# MCXA156 register map
Vendor: nxp.com; File version: 1.0
CPU: CM33 r2p0, little endian, no MPU, FPU, VTOR, 3 interrupt priority bits
Registers are 32-bit, read-write, reset 0x0 unless marked. A register's access mark holds for its fields unless they carry their own. Offsets are from the block's base; [hi:lo] are bit positions; 'fields as' and 'values as' point back to an identical list.

## SCG0 — SCG
Base 0x4008F000
0x00 VERID ro — Version ID Register
  [31:0] VERSION — SCG Version Number
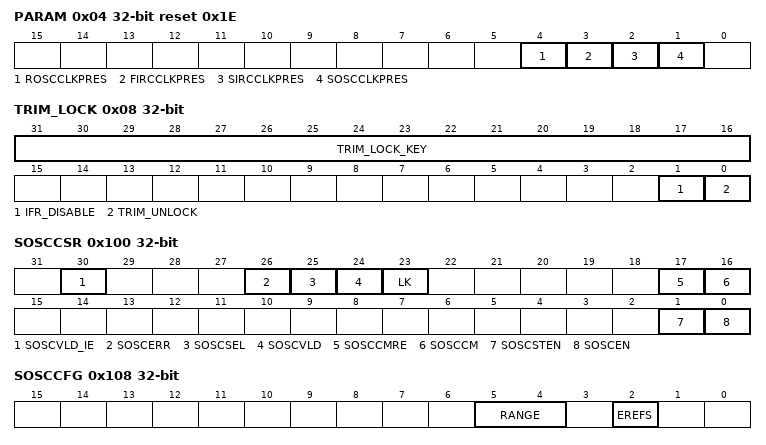
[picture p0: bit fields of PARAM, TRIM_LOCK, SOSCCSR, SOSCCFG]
0x04 PARAM ro reset 0x1E — Parameter Register
  [4] ROSCCLKPRES — ROSC Clock Present
    0=NOPRES (ROSC clock source is not present); 1=PRES (ROSC clock source is present)
  [3] FIRCCLKPRES — FIRC Clock Present
    0=NOPRES (FIRC clock source is not present); 1=PRES (FIRC clock source is present)
  [2] SIRCCLKPRES — SIRC Clock Present
    0=NOPRES (SIRC clock source is not present); 1=PRES (SIRC clock source is present)
  [1] SOSCCLKPRES — SOSC Clock Present
    0=NOPRES (SOSC clock source is not present); 1=PRES (SOSC clock source is present)
0x08 TRIM_LOCK
  [31:16] TRIM_LOCK_KEY
  [1] IFR_DISABLE
    0=ENABLED (IFR write access to SCG trim registers not disabled. The SCG Trim registers are reprogrammed with the IFR values after any system reset.); 1=DISABLED (IFR write access to SCG trim registers during system reset is blocked.)
  [0] TRIM_UNLOCK
    0=LOCKED (SCG Trim Registers locked and not writable.); 1=NOT_LOCKED (SCG Trim registers unlocked and writable.)
0x10 CSR ro reset 0x3000000 — Clock Status Register
  [26:24] SCS — System Clock Source
    1=SOSC; 2=SIRC; 3=FIRC; 4=ROSC
0x14 RCCR reset 0x3000000 — Run Clock Control Register
  [26:24] SCS — System Clock Source
    1=SOSC; 2=SIRC; 3=FIRC; 4=ROSC
0x100 SOSCCSR — SOSC Control Status Register
  [30] SOSCVLD_IE — SOSC Valid Interrupt Enable
    0=NOT_SOSC (SOSCVLD interrupt is not enabled); 1=SOSC (SOSCVLD interrupt is enabled)
  [26] SOSCERR write-1-clears — SOSC Clock Error
    0=DISABLED_OR_NO_ERROR (SOSC Clock Monitor is disabled or has not detected an error); 1=ENABLED_AND_ERROR (SOSC Clock Monitor is enabled and detected an error)
  [25] SOSCSEL ro — SOSC Selected
    0=NOT_SOSC (SOSC is not the system clock source); 1=SOSC (SOSC is the system clock source)
  [24] SOSCVLD ro — SOSC Valid
    0=DISABLED (SOSC is not enabled or clock is not valid); 1=ENABLED (SOSC is enabled and output clock is valid)
  [23] LK — Lock Register
    0=WRITE_ENABLED (This Control Status Register can be written); 1=WRITE_DISABLED (This Control Status Register cannot be written)
  [17] SOSCCMRE — SOSC Clock Monitor Reset Enable
    0=GENERATE_INTERRUPT (Clock monitor generates an interrupt when an error is detected); 1=GENERATE_RESET (Clock monitor generates a reset when an error is detected)
  [16] SOSCCM — SOSC Clock Monitor Enable
    0=DISABLED (SOSC Clock Monitor is disabled); 1=ENABLED (SOSC Clock Monitor is enabled)
  [1] SOSCSTEN — SOSC Stop Enable
    0=DISABLED (SOSC is disabled in Deep Sleep mode); 1=ENABLED (SOSC is enabled in Deep Sleep mode only if SOSCEN is set)
  [0] SOSCEN — SOSC Enable
    0=DISABLED (SOSC is disabled); 1=ENABLED (SOSC is enabled)
0x108 SOSCCFG — SOSC Configuration Register
  [5:4] RANGE — SOSC Range Select
    0=FREQ_16TO20MHz (Frequency range select of 8-16 MHz.); 1=LOW_FREQ (Frequency range select of 16-25 MHz.); 2=MEDIUM_FREQ (Frequency range select of 25-40 MHz.); 3=HIGH_FREQ (Frequency range select of 40-50 MHz.)
  [2] EREFS — External Reference Select
    0=EXTERNAL (External reference clock selected.); 1=INTERNAL (Internal crystal oscillator of OSC selected.)
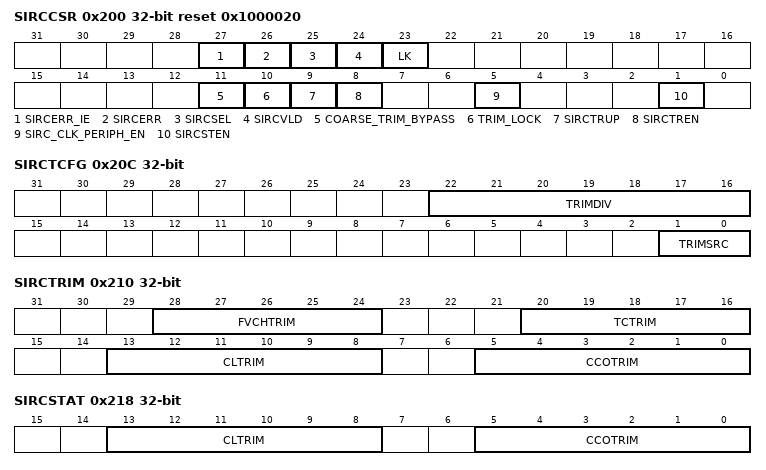
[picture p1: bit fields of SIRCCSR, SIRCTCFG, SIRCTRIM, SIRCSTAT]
0x200 SIRCCSR reset 0x1000020 — SIRC Control Status Register
  [27] SIRCERR_IE — SIRC Clock Error Interrupt Enable
    0=ERROR_NOT_DETECTED (SIRCERR interrupt is not enabled); 1=ERROR_DETECTED (SIRCERR interrupt is enabled)
  [26] SIRCERR write-1-clears — SIRC Clock Error
    0=ERROR_NOT_DETECTED (Error not detected with the SIRC trimming); 1=ERROR_DETECTED (Error detected with the SIRC trimming)
  [25] SIRCSEL ro — SIRC Selected
    0=NOT_SIRC (SIRC is not the system clock source); 1=SIRC (SIRC is the system clock source)
  [24] SIRCVLD ro — SIRC Valid
    0=DISABLED_OR_NOT_VALID (SIRC is not enabled or clock is not valid); 1=ENABLED_AND_VALID (SIRC is enabled and output clock is valid)
  [23] LK — Lock Register
    0=WRITE_ENABLED (Control Status Register can be written); 1=WRITE_DISABLED (Control Status Register cannot be written)
  [11] COARSE_TRIM_BYPASS — Coarse Auto Trim Bypass
    0=NOT_BYPASSED (SIRC Coarse Auto Trim NOT Bypassed); 1=BYPASSED (SIRC Coarse Auto Trim Bypassed)
  [10] TRIM_LOCK ro — SIRC TRIM LOCK
    0=SIRC_NOT_LOCKED (SIRC auto trim not locked to target frequency range); 1=SIRC_LOCKED (SIRC auto trim locked to target frequency range)
  [9] SIRCTRUP — SIRC Trim Update
    0=DISABLED (Disables SIRC trimming updates); 1=ENABLED (Enables SIRC trimming updates)
  [8] SIRCTREN — SIRC 12 MHz Trim Enable (SIRCCFG[RANGE]=1)
    0=DISABLED (Disables trimming SIRC to an external clock source); 1=ENABLED (Enables trimming SIRC to an external clock source)
  [5] SIRC_CLK_PERIPH_EN — SIRC Clock to Peripherals Enable
    0=DISABLED (SIRC clock to peripherals is disabled); 1=ENABLED (SIRC clock to peripherals is enabled)
  [1] SIRCSTEN — SIRC Stop Enable
    0=DISABLED (SIRC is disabled in Deep Sleep mode); 1=ENABLED (SIRC is enabled in Deep Sleep mode)
0x20C SIRCTCFG — SIRC Trim Configuration Register
  [22:16] TRIMDIV — SIRC Trim Pre-divider
  [1:0] TRIMSRC — Trim Source
    2=SOSC (SOSC. This option requires that SOSC be divided using the TRIMDIV field to get a frequency of 1 MHz.)
0x210 SIRCTRIM (reset mask 0xE0E0C0C0)
  [28:24] FVCHTRIM — Calibrates the replica voltage in FSU for CCO to get well frequency at initial period
  [20:16] TCTRIM — Trim Temp
  [13:8] CLTRIM
  [5:0] CCOTRIM
0x218 SIRCSTAT (reset mask 0xFFFFC0C0) — SIRC Auto-trimming Status Register
  [13:8] CLTRIM, [5:0] CCOTRIM
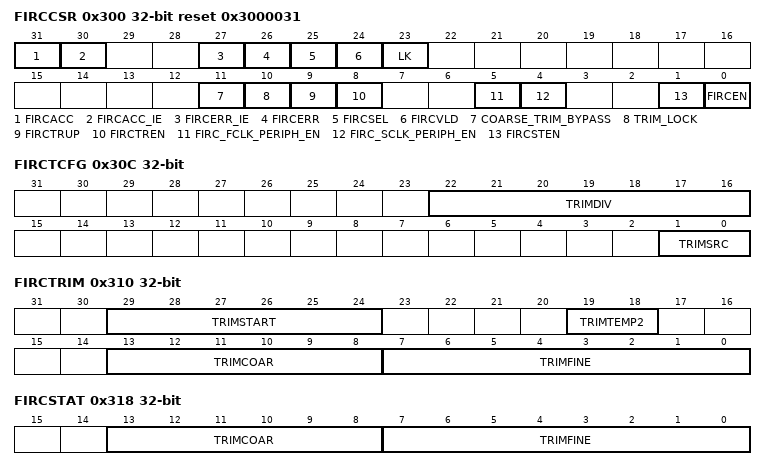
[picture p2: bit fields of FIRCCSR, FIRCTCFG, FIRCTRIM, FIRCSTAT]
0x300 FIRCCSR reset 0x3000031 (reset mask 0x7FFFFFFF) — FIRC Control Status Register
  [31] FIRCACC ro — FIRC Frequency Accurate
    0=NOT_ENABLED_OR_NOT_VALID (FIRC is not enabled or clock is not accurate.); 1=ENABLED_AND_VALID (FIRC is enabled and output clock is accurate after some preparation time which is obtained by counting FRO_HF clock.)
  [30] FIRCACC_IE — FIRC Accurate Interrupt Enable
    0=FIRCACCNOT (FIRCACC interrupt is not enabled); 1=FIRCACCYES (FIRCACC interrupt is enabled)
  [27] FIRCERR_IE — FIRC Clock Error Interrupt Enable
    0=ERROR_NOT_DETECTED (FIRCERR interrupt is not enabled); 1=ERROR_DETECTED (FIRCERR interrupt is enabled)
  [26] FIRCERR write-1-clears — FIRC Clock Error
    0=ERROR_NOT_DETECTED (Error not detected with the FIRC trimming); 1=ERROR_DETECTED (Error detected with the FIRC trimming)
  [25] FIRCSEL ro — FIRC Selected
    0=NOT_FIRC (FIRC is not the system clock source); 1=FIRC (FIRC is the system clock source)
  [24] FIRCVLD ro — FIRC Valid status
    0=NOT_ENABLED_OR_NOT_VALID (FIRC is not enabled or clock is not valid.); 1=ENABLED_AND_VALID (FIRC is enabled and output clock is valid. The clock is valid after there is an output clock from the FIRC analog.)
  [23] LK — Lock Register
    values as SIRCCSR.LK
  [11] COARSE_TRIM_BYPASS — Coarse Auto Trim Bypass
    0=NOT_BYPASSED (FIRC Coarse Auto Trim NOT Bypassed); 1=BYPASSED (FIRC Coarse Auto Trim Bypassed)
  [10] TRIM_LOCK ro — FIRC TRIM LOCK
    0=FIRC_NOT_LOCKED (FIRC auto trim not locked to target frequency range); 1=FIRC_LOCKED (FIRC auto trim locked to target frequency range)
  [9] FIRCTRUP — FIRC Trim Update
    0=DISABLED (Disables FIRC trimming updates); 1=ENABLED (Enables FIRC trimming updates)
  [8] FIRCTREN — FRO_HF Trim Enable
    0=DISABLED (Disables trimming FRO_HF by an external clock source); 1=ENABLED (Enables trimming FRO_HF by an external clock source)
  [5] FIRC_FCLK_PERIPH_EN — FRO_HF Clock to peripherals Enable
    0=DISABLED (FRO_HF to peripherals is disabled); 1=ENABLED (FRO_HF to peripherals is enabled)
  [4] FIRC_SCLK_PERIPH_EN — FIRC 48 MHz Clock to peripherals Enable
    0=DISABLED (FIRC 48 MHz to peripherals is disabled); 1=ENABLED (FIRC 48 MHz to peripherals is enabled)
  [1] FIRCSTEN — FIRC Stop Enable
    0=DISABLED_IN_STOP_MODES (FIRC is disabled in Deep Sleep mode); 1=ENABLED_IN_STOP_MODES (FIRC is enabled in Deep Sleep mode)
  [0] FIRCEN — FIRC Enable
    0=DISABLED (FIRC is disabled); 1=ENABLED (FIRC is enabled)
0x308 FIRCCFG reset 0x3 — FIRC Configuration Register
  [3:1] FREQ_SEL — Frequency select
    1=FIRC_48MHz_192S (48 MHz FIRC clock selected, divided from 192 MHz); 3=FIRC_64MHz (64 MHz FIRC clock selected); 5=FIRC_96MHz (96 MHz FIRC clock selected); 7=FIRC_192MHz (192 MHz FIRC clock selected)
0x30C FIRCTCFG — FIRC Trim Configuration Register
  [22:16] TRIMDIV — FIRC Trim Pre-divider
  [1:0] TRIMSRC — Trim Source
    0=USB0 (USB0 Start of Frame (1 KHz). This option does not use TRIMDIV .); 2=SOSC (SOSC. This option requires that SOSC be divided using the TRIMDIV field to get a frequency of 1 MHz.)
0x310 FIRCTRIM (reset mask 0xC0F3C000)
  [29:24] TRIMSTART
  [19:18] TRIMTEMP2 — Trim Temperature2
  [13:8] TRIMCOAR — Trim Coarse
  [7:0] TRIMFINE
0x318 FIRCSTAT (reset mask 0xFFFFC000) — FIRC Auto-trimming Status Register
  [13:8] TRIMCOAR — Trim Coarse
  [7:0] TRIMFINE
0x31C FIRCATC1 reset 0x9678 — FIRC Auto-trimming Counter 1
  [15:0] IDEALC — Ideal Counter
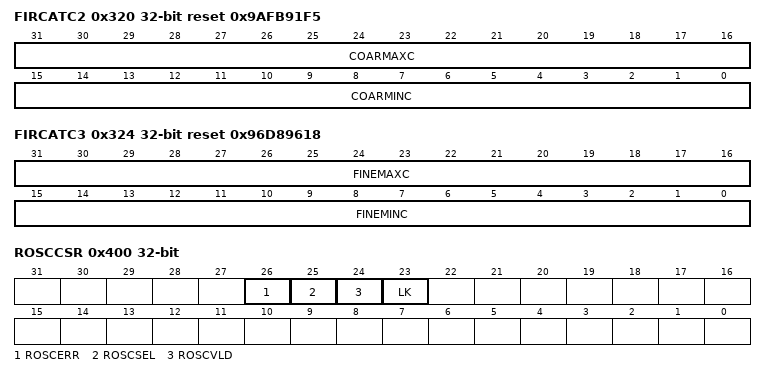
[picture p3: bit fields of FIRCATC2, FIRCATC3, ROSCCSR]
0x320 FIRCATC2 reset 0x9AFB91F5 — FIRC Auto-trimming Counter 2
  [31:16] COARMAXC — Coarse Trim Maximum Counter
  [15:0] COARMINC — Coarse Trim Minimum Counter
0x324 FIRCATC3 reset 0x96D89618 — FIRC Auto-trimming Counter 2
  [31:16] FINEMAXC — Fine Trim Maximum Counter
  [15:0] FINEMINC — Fine Trim Minimum Counter
0x400 ROSCCSR — ROSC Control Status Register
  [26] ROSCERR write-1-clears — ROSC Clock Error
    0=DISABLED_OR_NO_ERROR (ROSC Clock has not detected an error); 1=ENABLED_AND_ERROR (ROSC Clock has detected an error)
  [25] ROSCSEL ro — ROSC Selected
    0=NOT_ROSC (ROSC is not the system clock source); 1=ROSC (ROSC is the system clock source)
  [24] ROSCVLD ro — ROSC Valid
    0=DISABLED_OR_NOT_VALID (ROSC is not enabled or clock is not valid); 1=ENABLED_AND_VALID (ROSC is enabled and output clock is valid)
  [23] LK — Lock Register
    values as SIRCCSR.LK
